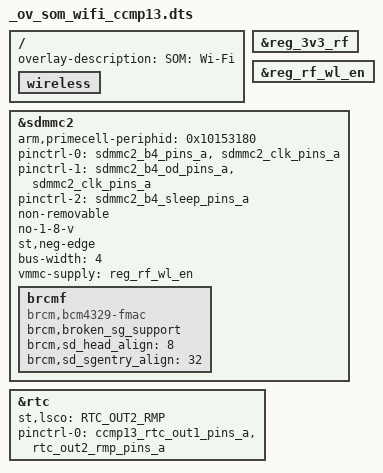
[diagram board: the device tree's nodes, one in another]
/*
 * Copyright 2022-2024 Digi International Inc.
 *
 * Permission to use, copy, modify, and/or distribute this software for any
 * purpose with or without fee is hereby granted, provided that the above
 * copyright notice and this permission notice appear in all copies.
 * THE SOFTWARE IS PROVIDED "AS IS" AND THE AUTHOR DISCLAIMS ALL WARRANTIES
 * WITH REGARD TO THIS SOFTWARE INCLUDING ALL IMPLIED WARRANTIES OF
 * MERCHANTABILITY AND FITNESS. IN NO EVENT SHALL THE AUTHOR BE LIABLE FOR
 * ANY SPECIAL, DIRECT, INDIRECT, OR CONSEQUENTIAL DAMAGES OR ANY DAMAGES
 * WHATSOEVER RESULTING FROM LOSS OF USE, DATA OR PROFITS, WHETHER IN AN
 * ACTION OF CONTRACT, NEGLIGENCE OR OTHER TORTIOUS ACTION, ARISING OUT OF
 * OR IN CONNECTION WITH THE USE OR PERFORMANCE OF THIS SOFTWARE.
 */

#include <dt-bindings/rtc/rtc-stm32.h>

/dts-v1/;
/plugin/;

/ {
	fragment@0 {
		target-path = "/";
		__overlay__ {
			overlay-description = "SOM: Wi-Fi";
			wireless {
				/* U-Boot will fill in the MAC address here */
			};
		};
	};

	/* Enable the RF regulator */
	fragment@1 {
		target = <&reg_3v3_rf>;
		__overlay__ {
			status = "okay";
		};
	};

	/* Enable the WL regulator */
	fragment@2 {
		target = <&reg_rf_wl_en>;
		__overlay__ {
			status = "okay";
		};
	};

	/* Enable SDMMC2 (Wireless) */
	fragment@3 {
		target = <&sdmmc2>;
		__overlay__ {
			arm,primecell-periphid = <0x10153180>;
			pinctrl-names = "default", "opendrain", "sleep";
			pinctrl-0 = <&sdmmc2_b4_pins_a &sdmmc2_clk_pins_a>;
			pinctrl-1 = <&sdmmc2_b4_od_pins_a &sdmmc2_clk_pins_a>;
			pinctrl-2 = <&sdmmc2_b4_sleep_pins_a>;
			non-removable;
			no-1-8-v;
			st,neg-edge;
			bus-width = <4>;
			vmmc-supply = <&reg_rf_wl_en>;
			status = "okay";

			brcmf {
				compatible = "brcm,bcm4329-fmac";
				brcm,broken_sg_support;
		                brcm,sd_head_align = /bits/  16 <8>;
				brcm,sd_sgentry_align = /bits/ 16 <32>;
			};
		};
	};

	/* Enable External 32kHz Low-Power Oscillator */
	fragment@4 {
		target = <&rtc>;
		__overlay__ {
			st,lsco = <RTC_OUT2_RMP>;
			pinctrl-0 = <&ccmp13_rtc_out1_pins_a &rtc_out2_rmp_pins_a>;
			pinctrl-names = "default";
		};
	};
};
